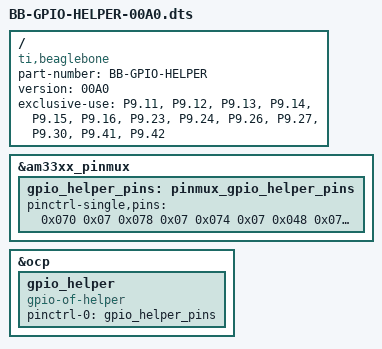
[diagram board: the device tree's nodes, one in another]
/dts-v1/;
/plugin/;

/*
 * BeagleBone Black GPIO Helper Overlay
 * Exports commonly used GPIO pins for easy userspace access
 */

/ {
    compatible = "ti,beaglebone", "ti,beaglebone-black";
    
    /* identification */
    part-number = "BB-GPIO-HELPER";
    version = "00A0";
    
    /* state the resources this cape uses */
    exclusive-use =
        /* GPIO pins */
        "P9.11",    /* gpio0_30 */
        "P9.12",    /* gpio1_28 */
        "P9.13",    /* gpio0_31 */
        "P9.14",    /* gpio1_18 */
        "P9.15",    /* gpio1_16 */
        "P9.16",    /* gpio1_19 */
        "P9.23",    /* gpio1_17 */
        "P9.24",    /* gpio0_15 */
        "P9.26",    /* gpio0_14 */
        "P9.27",    /* gpio3_19 */
        "P9.30",    /* gpio3_16 */
        "P9.41",    /* gpio0_20 */
        "P9.42";    /* gpio0_7  */

    fragment@0 {
        target = <&am33xx_pinmux>;
        __overlay__ {
            gpio_helper_pins: pinmux_gpio_helper_pins {
                pinctrl-single,pins = <
                    0x070 0x07  /* P9_11: gpio0_30, MODE7 */
                    0x078 0x07  /* P9_12: gpio1_28, MODE7 */
                    0x074 0x07  /* P9_13: gpio0_31, MODE7 */
                    0x048 0x07  /* P9_14: gpio1_18, MODE7 */
                    0x040 0x07  /* P9_15: gpio1_16, MODE7 */
                    0x04c 0x07  /* P9_16: gpio1_19, MODE7 */
                    0x044 0x07  /* P9_23: gpio1_17, MODE7 */
                    0x184 0x07  /* P9_24: gpio0_15, MODE7 */
                    0x180 0x07  /* P9_26: gpio0_14, MODE7 */
                    0x1a4 0x07  /* P9_27: gpio3_19, MODE7 */
                    0x198 0x07  /* P9_30: gpio3_16, MODE7 */
                    0x1b4 0x07  /* P9_41: gpio0_20, MODE7 */
                    0x164 0x07  /* P9_42: gpio0_7,  MODE7 */
                >;
            };
        };
    };

    fragment@1 {
        target = <&ocp>;
        __overlay__ {
            gpio_helper {
                compatible = "gpio-of-helper";
                status = "okay";
                pinctrl-names = "default";
                pinctrl-0 = <&gpio_helper_pins>;
            };
        };
    };
};
